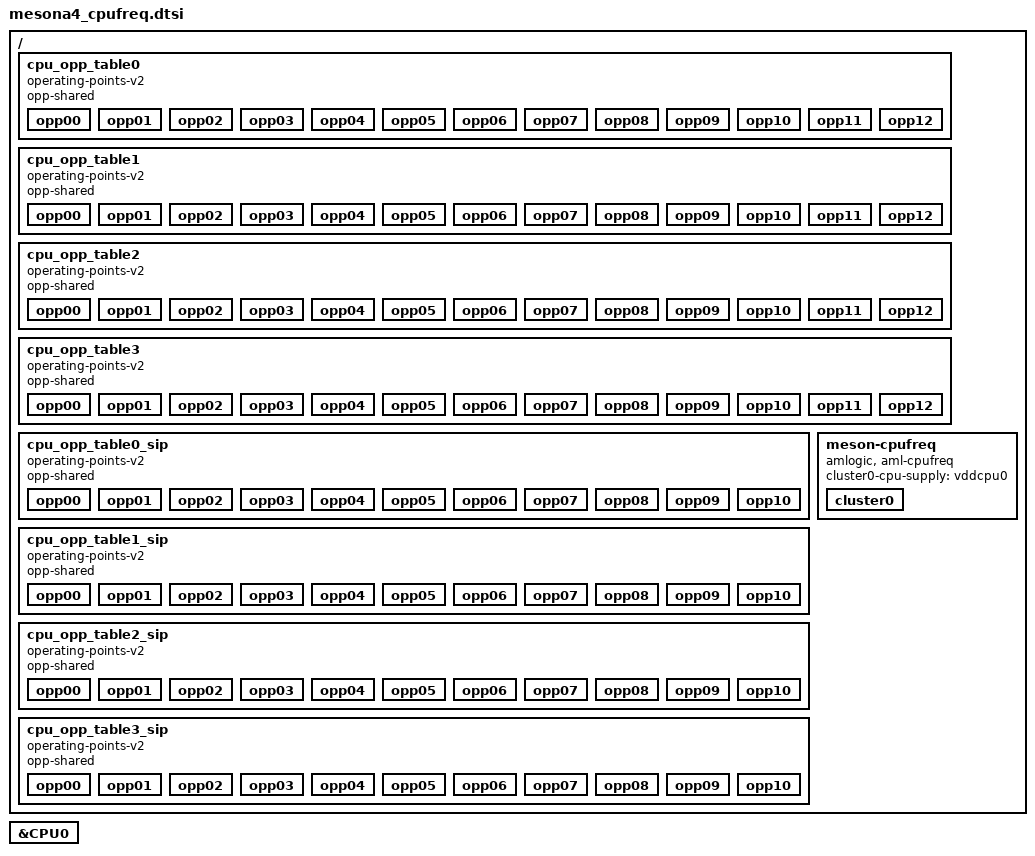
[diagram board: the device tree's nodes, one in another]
// SPDX-License-Identifier: (GPL-2.0+ OR MIT)
/*
 * Copyright (c) 2019 Amlogic, Inc. All rights reserved.
 */
/ {
	cpu_opp_table0: cpu_opp_table0 {
			compatible = "operating-points-v2";
			opp-shared;

			opp00 {
				opp-hz = /bits/ 64 <100000000>;
				opp-microvolt = <779000>;
			};
			opp01 {
				opp-hz = /bits/ 64 <250000000>;
				opp-microvolt = <779000>;
			};
			opp02 {
				opp-hz = /bits/ 64 <500000000>;
				opp-microvolt = <779000>;
			};
			opp03 {
				opp-hz = /bits/ 64 <666666000>;
				opp-microvolt = <779000>;
			};
			opp04 {
				opp-hz = /bits/ 64 <1000000000>;
				opp-microvolt = <779000>;
			};
			opp05 {
				opp-hz = /bits/ 64 <1200000000>;
				opp-microvolt = <809000>;
			};
			opp06 {
				opp-hz = /bits/ 64 <1404000000>;
				opp-microvolt = <839000>;
			};
			opp07 {
				opp-hz = /bits/ 64 <1500000000>;
				opp-microvolt = <869000>;
			};
			opp08 {
				opp-hz = /bits/ 64 <1608000000>;
				opp-microvolt = <899000>;
			};
			opp09 {
				opp-hz = /bits/ 64 <1704000000>;
				opp-microvolt = <929000>;
			};
			opp10 {
				opp-hz = /bits/ 64 <1800000000>;
				opp-microvolt = <959000>;
			};
			opp11 {
				opp-hz = /bits/ 64 <1920000000>;
				opp-microvolt = <999000>;
			};
			opp12 {
				opp-hz = /bits/ 64 <2016000000>;
				opp-microvolt = <1009000>;
			};
		};

		cpu_opp_table1: cpu_opp_table1 {
			compatible = "operating-points-v2";
			opp-shared;

			opp00 {
				opp-hz = /bits/ 64 <100000000>;
				opp-microvolt = <779000>;
			};
			opp01 {
				opp-hz = /bits/ 64 <250000000>;
				opp-microvolt = <779000>;
			};
			opp02 {
				opp-hz = /bits/ 64 <500000000>;
				opp-microvolt = <779000>;
			};
			opp03 {
				opp-hz = /bits/ 64 <666666000>;
				opp-microvolt = <779000>;
			};
			opp04 {
				opp-hz = /bits/ 64 <1000000000>;
				opp-microvolt = <779000>;
			};
			opp05 {
				opp-hz = /bits/ 64 <1200000000>;
				opp-microvolt = <809000>;
			};
			opp06 {
				opp-hz = /bits/ 64 <1404000000>;
				opp-microvolt = <839000>;
			};
			opp07 {
				opp-hz = /bits/ 64 <1500000000>;
				opp-microvolt = <869000>;
			};
			opp08 {
				opp-hz = /bits/ 64 <1608000000>;
				opp-microvolt = <899000>;
			};
			opp09 {
				opp-hz = /bits/ 64 <1704000000>;
				opp-microvolt = <929000>;
			};
			opp10 {
				opp-hz = /bits/ 64 <1800000000>;
				opp-microvolt = <959000>;
			};
			opp11 {
				opp-hz = /bits/ 64 <1920000000>;
				opp-microvolt = <999000>;
			};
			opp12 {
				opp-hz = /bits/ 64 <2016000000>;
				opp-microvolt = <1009000>;
			};
		};

		cpu_opp_table2: cpu_opp_table2 {
			compatible = "operating-points-v2";
			opp-shared;

			opp00 {
				opp-hz = /bits/ 64 <100000000>;
				opp-microvolt = <739000>;
			};
			opp01 {
				opp-hz = /bits/ 64 <250000000>;
				opp-microvolt = <739000>;
			};
			opp02 {
				opp-hz = /bits/ 64 <500000000>;
				opp-microvolt = <739000>;
			};
			opp03 {
				opp-hz = /bits/ 64 <666666000>;
				opp-microvolt = <739000>;
			};
			opp04 {
				opp-hz = /bits/ 64 <1000000000>;
				opp-microvolt = <739000>;
			};
			opp05 {
				opp-hz = /bits/ 64 <1200000000>;
				opp-microvolt = <769000>;
			};
			opp06 {
				opp-hz = /bits/ 64 <1404000000>;
				opp-microvolt = <799000>;
			};
			opp07 {
				opp-hz = /bits/ 64 <1500000000>;
				opp-microvolt = <829000>;
			};
			opp08 {
				opp-hz = /bits/ 64 <1608000000>;
				opp-microvolt = <859000>;
			};
			opp09 {
				opp-hz = /bits/ 64 <1704000000>;
				opp-microvolt = <889000>;
			};
			opp10 {
				opp-hz = /bits/ 64 <1800000000>;
				opp-microvolt = <919000>;
			};
			opp11 {
				opp-hz = /bits/ 64 <1920000000>;
				opp-microvolt = <959000>;
			};
			opp12 {
				opp-hz = /bits/ 64 <2016000000>;
				opp-microvolt = <999000>;
			};
		};

		cpu_opp_table3: cpu_opp_table3 {
			compatible = "operating-points-v2";
			opp-shared;

			opp00 {
				opp-hz = /bits/ 64 <100000000>;
				opp-microvolt = <729000>;
			};
			opp01 {
				opp-hz = /bits/ 64 <250000000>;
				opp-microvolt = <729000>;
			};
			opp02 {
				opp-hz = /bits/ 64 <500000000>;
				opp-microvolt = <729000>;
			};
			opp03 {
				opp-hz = /bits/ 64 <666666000>;
				opp-microvolt = <729000>;
			};
			opp04 {
				opp-hz = /bits/ 64 <1000000000>;
				opp-microvolt = <729000>;
			};
			opp05 {
				opp-hz = /bits/ 64 <1200000000>;
				opp-microvolt = <729000>;
			};
			opp06 {
				opp-hz = /bits/ 64 <1404000000>;
				opp-microvolt = <749000>;
			};
			opp07 {
				opp-hz = /bits/ 64 <1500000000>;
				opp-microvolt = <779000>;
			};
			opp08 {
				opp-hz = /bits/ 64 <1608000000>;
				opp-microvolt = <799000>;
			};
			opp09 {
				opp-hz = /bits/ 64 <1704000000>;
				opp-microvolt = <829000>;
			};
			opp10 {
				opp-hz = /bits/ 64 <1800000000>;
				opp-microvolt = <859000>;
			};
			opp11 {
				opp-hz = /bits/ 64 <1920000000>;
				opp-microvolt = <899000>;
			};
			opp12 {
				opp-hz = /bits/ 64 <2016000000>;
				opp-microvolt = <929000>;
			};
		};

	cpu_opp_table0_sip: cpu_opp_table0_sip {
			compatible = "operating-points-v2";
			opp-shared;

			opp00 {
				opp-hz = /bits/ 64 <100000000>;
				opp-microvolt = <779000>;
			};
			opp01 {
				opp-hz = /bits/ 64 <250000000>;
				opp-microvolt = <779000>;
			};
			opp02 {
				opp-hz = /bits/ 64 <500000000>;
				opp-microvolt = <779000>;
			};
			opp03 {
				opp-hz = /bits/ 64 <666666000>;
				opp-microvolt = <779000>;
			};
			opp04 {
				opp-hz = /bits/ 64 <1000000000>;
				opp-microvolt = <779000>;
			};
			opp05 {
				opp-hz = /bits/ 64 <1200000000>;
				opp-microvolt = <809000>;
			};
			opp06 {
				opp-hz = /bits/ 64 <1404000000>;
				opp-microvolt = <839000>;
			};
			opp07 {
				opp-hz = /bits/ 64 <1500000000>;
				opp-microvolt = <869000>;
			};
			opp08 {
				opp-hz = /bits/ 64 <1608000000>;
				opp-microvolt = <899000>;
			};
			opp09 {
				opp-hz = /bits/ 64 <1704000000>;
				opp-microvolt = <929000>;
			};
			opp10 {
				opp-hz = /bits/ 64 <1800000000>;
				opp-microvolt = <959000>;
			};
		};

		cpu_opp_table1_sip: cpu_opp_table1_sip {
			compatible = "operating-points-v2";
			opp-shared;

			opp00 {
				opp-hz = /bits/ 64 <100000000>;
				opp-microvolt = <779000>;
			};
			opp01 {
				opp-hz = /bits/ 64 <250000000>;
				opp-microvolt = <779000>;
			};
			opp02 {
				opp-hz = /bits/ 64 <500000000>;
				opp-microvolt = <779000>;
			};
			opp03 {
				opp-hz = /bits/ 64 <666666000>;
				opp-microvolt = <779000>;
			};
			opp04 {
				opp-hz = /bits/ 64 <1000000000>;
				opp-microvolt = <779000>;
			};
			opp05 {
				opp-hz = /bits/ 64 <1200000000>;
				opp-microvolt = <809000>;
			};
			opp06 {
				opp-hz = /bits/ 64 <1404000000>;
				opp-microvolt = <839000>;
			};
			opp07 {
				opp-hz = /bits/ 64 <1500000000>;
				opp-microvolt = <869000>;
			};
			opp08 {
				opp-hz = /bits/ 64 <1608000000>;
				opp-microvolt = <899000>;
			};
			opp09 {
				opp-hz = /bits/ 64 <1704000000>;
				opp-microvolt = <929000>;
			};
			opp10 {
				opp-hz = /bits/ 64 <1800000000>;
				opp-microvolt = <959000>;
			};
		};

		cpu_opp_table2_sip: cpu_opp_table2_sip {
			compatible = "operating-points-v2";
			opp-shared;

			opp00 {
				opp-hz = /bits/ 64 <100000000>;
				opp-microvolt = <739000>;
			};
			opp01 {
				opp-hz = /bits/ 64 <250000000>;
				opp-microvolt = <739000>;
			};
			opp02 {
				opp-hz = /bits/ 64 <500000000>;
				opp-microvolt = <739000>;
			};
			opp03 {
				opp-hz = /bits/ 64 <666666000>;
				opp-microvolt = <739000>;
			};
			opp04 {
				opp-hz = /bits/ 64 <1000000000>;
				opp-microvolt = <739000>;
			};
			opp05 {
				opp-hz = /bits/ 64 <1200000000>;
				opp-microvolt = <769000>;
			};
			opp06 {
				opp-hz = /bits/ 64 <1404000000>;
				opp-microvolt = <799000>;
			};
			opp07 {
				opp-hz = /bits/ 64 <1500000000>;
				opp-microvolt = <829000>;
			};
			opp08 {
				opp-hz = /bits/ 64 <1608000000>;
				opp-microvolt = <859000>;
			};
			opp09 {
				opp-hz = /bits/ 64 <1704000000>;
				opp-microvolt = <889000>;
			};
			opp10 {
				opp-hz = /bits/ 64 <1800000000>;
				opp-microvolt = <919000>;
			};
		};

		cpu_opp_table3_sip: cpu_opp_table3_sip {
			compatible = "operating-points-v2";
			opp-shared;

			opp00 {
				opp-hz = /bits/ 64 <100000000>;
				opp-microvolt = <729000>;
			};
			opp01 {
				opp-hz = /bits/ 64 <250000000>;
				opp-microvolt = <729000>;
			};
			opp02 {
				opp-hz = /bits/ 64 <500000000>;
				opp-microvolt = <729000>;
			};
			opp03 {
				opp-hz = /bits/ 64 <666666000>;
				opp-microvolt = <729000>;
			};
			opp04 {
				opp-hz = /bits/ 64 <1000000000>;
				opp-microvolt = <729000>;
			};
			opp05 {
				opp-hz = /bits/ 64 <1200000000>;
				opp-microvolt = <729000>;
			};
			opp06 {
				opp-hz = /bits/ 64 <1404000000>;
				opp-microvolt = <749000>;
			};
			opp07 {
				opp-hz = /bits/ 64 <1500000000>;
				opp-microvolt = <779000>;
			};
			opp08 {
				opp-hz = /bits/ 64 <1608000000>;
				opp-microvolt = <799000>;
			};
			opp09 {
				opp-hz = /bits/ 64 <1704000000>;
				opp-microvolt = <829000>;
			};
			opp10 {
				opp-hz = /bits/ 64 <1800000000>;
				opp-microvolt = <859000>;
			};
		};

	meson-cpufreq {
		compatible = "amlogic, aml-cpufreq";
		status = "okay";

		cluster0-cpu-supply = <&vddcpu0>;

		cluster0 {
			clocks = <&scmi_clk CLKID_CPU_CLK>;
			clock-names = "cpuclk";
			voltage-tolerance = <0>;
			clock-latency = <50000>;
			//skip_volt_scaling;
			cluster_cores = <0 1 2 3>;
			pdvfs_enabled;
		};
	};
};/* end of / */

&CPU0 {
	#cooling-cells = <2>;
	operating-points-v2 = <&cpu_opp_table0>,
					<&cpu_opp_table1>,
					<&cpu_opp_table2>,
					<&cpu_opp_table3>;
};
